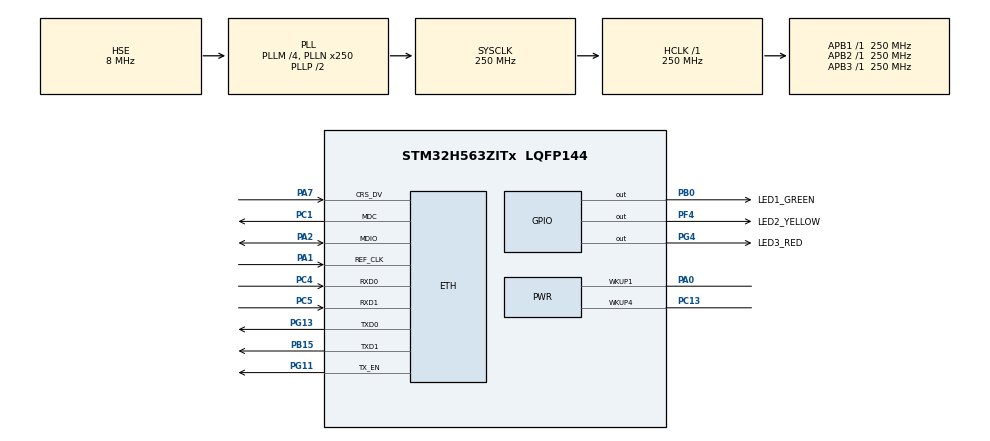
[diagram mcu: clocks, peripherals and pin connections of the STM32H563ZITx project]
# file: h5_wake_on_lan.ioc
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BOOTPATH.BootPathName=LEGACY
BOOTPATH.UserSelectedBootPath=LEGACY
CORTEX_M33_NS.userName=CORTEX_M33
ETH.MediaInterface=HAL_ETH_RMII_MODE
Mcu.Family=STM32H5
Mcu.Name=STM32H563ZITx
Mcu.Package=LQFP144
NETXDUO.ETH_ON=1
NETXDUO.Initialize_TCP_protocol=false
NETXDUO.LAN_8742=1
NETXDUO.NX_APP_IP_INSTANCE_THREAD_SIZE=1024 * 2
NETXDUO.NX_APP_MEM_POOL_SIZE=1024 * 30
NETXDUO.NX_APP_PACKET_POOL_SIZE=150
NETXDUO.NX_APP_THREAD_STACK_SIZE=1024 * 2
NETXDUO.NX_ENABLE_INTERFACE_CAPABILITY=true
NETXDUO.NetXDuo_Generate_Init_Code=true
NVIC.ETH_IRQn=true\:7\:0\:true\:false\:true\:false\:true\:true\:true
NVIC.ETH_WKUP_IRQn=true\:0\:0\:false\:false\:true\:false\:true\:true\:true
NVIC.PriorityGroup=NVIC_PRIORITYGROUP_4
NVIC.TIM6_IRQn=true\:15\:0\:false\:false\:true\:false\:false\:true\:true
NVIC.TimeBase=TIM6_IRQn
NVIC.TimeBaseIP=TIM6
NetXDuo.BSP.number=1
NetXDuo0.BSP.STBoard=false
NetXDuo0.BSP.api=BSP_COMPONENT_DRIVER
NetXDuo0.BSP.component=lan8742
NetXDuo0.BSP.instance=lan8742
NetXDuo0.BSP.name=LAN_Component
NetXDuo0.BSP.semaphore=SEMA_lan8742
NetXDuo0.BSP.solution=lan8742
PA0.Mode=WakeUp1
PA0.Signal=PWR_WKUP1
PA1.Mode=RMII
PA1.Signal=ETH_REF_CLK
PA2.Mode=RMII
PA2.Signal=ETH_MDIO
PA7.Mode=RMII
PA7.Signal=ETH_CRS_DV
PB0.GPIO_Label=LED1_GREEN
PB0.Signal=GPIO_Output
PB15.Mode=RMII
PB15.Signal=ETH_TXD1
PC1.Mode=RMII
PC1.Signal=ETH_MDC
PC13.Mode=WakeUp4
PC13.Signal=PWR_WKUP4
PC4.Mode=RMII
PC4.Signal=ETH_RXD0
PC5.Mode=RMII
PC5.Signal=ETH_RXD1
PF4.GPIO_Label=LED2_YELLOW
PF4.Signal=GPIO_Output
PG11.Mode=RMII
PG11.Signal=ETH_TX_EN
PG13.Mode=RMII
PG13.Signal=ETH_TXD0
PG4.GPIO_Label=LED3_RED
PG4.Signal=GPIO_Output
PH0-OSC_IN(PH0).Mode=HSE-DIG-External-Clock-Source
PH0-OSC_IN(PH0).Signal=RCC_OSC_IN
ProjectManager.HeapSize=0x200
ProjectManager.StackSize=0x400
ProjectManager.TargetToolchain=STM32CubeIDE
RCC.ADCFreq_Value=250000000
RCC.AHBFreq_Value=250000000
RCC.APB1Freq_Value=250000000
RCC.APB1TimFreq_Value=250000000
RCC.APB2Freq_Value=250000000
RCC.APB2TimFreq_Value=250000000
RCC.APB3Freq_Value=250000000
RCC.CSI_VALUE=4000000
RCC.CortexFreq_Value=250000000
RCC.EPOD_VALUE=8000000
RCC.HCLKFreq_Value=250000000
RCC.HSE_VALUE=8000000
RCC.HSI48_VALUE=48000000
RCC.HSI_VALUE=64000000
RCC.LSE_VALUE=32768
RCC.LSIRC_VALUE=32000
RCC.PLLFRACN=0
RCC.PLLM=4
RCC.PLLN=250
RCC.PLLSourceVirtual=RCC_PLL1_SOURCE_HSE
RCC.SYSCLKFreq_VALUE=250000000
RCC.SYSCLKSource=RCC_SYSCLKSOURCE_PLLCLK
RCC.USBFreq_Value=48000000
RCC.VCOOutputFreq_Value=500000000
VP_BOOTPATH_VS_BOOTPATH.Mode=BP_Activate
VP_ICACHE_VS_ICACHE.Mode=DefaultMode
VP_MEMORYMAP_VS_MEMORYMAP.Mode=CurAppReg
VP_NETXDUO_VS_EthernetOoPhyOoInterface.Mode=LAN8742_Phy_Interface
VP_NETXDUO_VS_NXOoCore.Mode=NX_Core
VP_NETXDUO_VS_NetworkOoInterface.Mode=Ethernet_Interface
VP_PWR_VS_DBSignals.Mode=DisableDeadBatterySignals
VP_PWR_VS_LPOM.Mode=PowerOptimisation
VP_PWR_VS_SECSignals.Mode=Security/Privilege
VP_SYS_VS_tim6.Mode=TIM6
VP_THREADX_VS_RTOSJjThreadXJjCoreJjDefault.Mode=Core_Default
board=custom

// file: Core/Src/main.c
/* USER CODE BEGIN Header */
/**
  ******************************************************************************
  * @file           : main.c
  * @brief          : Main program body
  ******************************************************************************
  * @attention
  *
  * Copyright (c) 2024 STMicroelectronics.
  * All rights reserved.
  *
  * This software is licensed under terms that can be found in the LICENSE file
  * in the root directory of this software component.
  * If no LICENSE file comes with this software, it is provided AS-IS.
  *
  ******************************************************************************
  */
/* USER CODE END Header */
#include "app_threadx.h"
#include "main.h"
#include "string.h"

ETH_TxPacketConfig TxConfig;
ETH_DMADescTypeDef  DMARxDscrTab[ETH_RX_DESC_CNT]; /* Ethernet Rx DMA Descriptors */
ETH_DMADescTypeDef  DMATxDscrTab[ETH_TX_DESC_CNT]; /* Ethernet Tx DMA Descriptors */

ETH_HandleTypeDef heth;

/* USER CODE BEGIN PV */
UCHAR memory_area[MEMORY_SIZE];
/* USER CODE END PV */

void SystemClock_Config(void);
static void MX_GPIO_Init(void);
static void MX_ETH_Init(void);
static void MX_ICACHE_Init(void);

int main(void)
{

  /* MCU Configuration--------------------------------------------------------*/

  /* Reset of all peripherals, Initializes the Flash interface and the Systick. */
  HAL_Init();

  /* Configure the system clock */
  SystemClock_Config();

  /* Initialize all configured peripherals */
  MX_GPIO_Init();
  MX_ETH_Init();
  MX_ICACHE_Init();
  /* USER CODE BEGIN 2 */
  // Inizializzazione dell'area di memoria con valori dummy
  for (ULONG i = 0; i < MEMORY_SIZE; i++)
  {
    memory_area[i] = 'a';
  }
  /* USER CODE END 2 */

  MX_ThreadX_Init();

  /* We should never get here as control is now taken by the scheduler */
  /* Infinite loop */
  while (1)
  {

  }
}

void SystemClock_Config(void)
{
  RCC_OscInitTypeDef RCC_OscInitStruct = {0};
  RCC_ClkInitTypeDef RCC_ClkInitStruct = {0};

  /** Configure the main internal regulator output voltage
  */
  __HAL_PWR_VOLTAGESCALING_CONFIG(PWR_REGULATOR_VOLTAGE_SCALE0);

  while(!__HAL_PWR_GET_FLAG(PWR_FLAG_VOSRDY)) {}

  /** Initializes the RCC Oscillators according to the specified parameters
  * in the RCC_OscInitTypeDef structure.
  */
  RCC_OscInitStruct.OscillatorType = RCC_OSCILLATORTYPE_HSE;
  RCC_OscInitStruct.HSEState = RCC_HSE_BYPASS_DIGITAL;
  RCC_OscInitStruct.PLL.PLLState = RCC_PLL_ON;
  RCC_OscInitStruct.PLL.PLLSource = RCC_PLL1_SOURCE_HSE;
  RCC_OscInitStruct.PLL.PLLM = 4;
  RCC_OscInitStruct.PLL.PLLN = 250;
  RCC_OscInitStruct.PLL.PLLP = 2;
  RCC_OscInitStruct.PLL.PLLQ = 2;
  RCC_OscInitStruct.PLL.PLLR = 2;
  RCC_OscInitStruct.PLL.PLLRGE = RCC_PLL1_VCIRANGE_1;
  RCC_OscInitStruct.PLL.PLLVCOSEL = RCC_PLL1_VCORANGE_WIDE;
  RCC_OscInitStruct.PLL.PLLFRACN = 0;
  if (HAL_RCC_OscConfig(&RCC_OscInitStruct) != HAL_OK)
  {
    Error_Handler();
  }

  /** Initializes the CPU, AHB and APB buses clocks
  */
  RCC_ClkInitStruct.ClockType = RCC_CLOCKTYPE_HCLK|RCC_CLOCKTYPE_SYSCLK
                              |RCC_CLOCKTYPE_PCLK1|RCC_CLOCKTYPE_PCLK2
                              |RCC_CLOCKTYPE_PCLK3;
  RCC_ClkInitStruct.SYSCLKSource = RCC_SYSCLKSOURCE_PLLCLK;
  RCC_ClkInitStruct.AHBCLKDivider = RCC_SYSCLK_DIV1;
  RCC_ClkInitStruct.APB1CLKDivider = RCC_HCLK_DIV1;
  RCC_ClkInitStruct.APB2CLKDivider = RCC_HCLK_DIV1;
  RCC_ClkInitStruct.APB3CLKDivider = RCC_HCLK_DIV1;

  if (HAL_RCC_ClockConfig(&RCC_ClkInitStruct, FLASH_LATENCY_5) != HAL_OK)
  {
    Error_Handler();
  }
}

static void MX_ETH_Init(void)
{

   static uint8_t MACAddr[6];

  heth.Instance = ETH;
  MACAddr[0] = 0x00;
  MACAddr[1] = 0x80;
  MACAddr[2] = 0xE1;
  MACAddr[3] = 0x00;
  MACAddr[4] = 0x00;
  MACAddr[5] = 0x00;
  heth.Init.MACAddr = &MACAddr[0];
  heth.Init.MediaInterface = HAL_ETH_RMII_MODE;
  heth.Init.TxDesc = DMATxDscrTab;
  heth.Init.RxDesc = DMARxDscrTab;
  heth.Init.RxBuffLen = 1524;

  if (HAL_ETH_Init(&heth) != HAL_OK)
  {
    Error_Handler();
  }

  memset(&TxConfig, 0 , sizeof(ETH_TxPacketConfig));
  TxConfig.Attributes = ETH_TX_PACKETS_FEATURES_CSUM | ETH_TX_PACKETS_FEATURES_CRCPAD;
  TxConfig.ChecksumCtrl = ETH_CHECKSUM_IPHDR_PAYLOAD_INSERT_PHDR_CALC;
  TxConfig.CRCPadCtrl = ETH_CRC_PAD_INSERT;

}

static void MX_ICACHE_Init(void)
{

  /** Enable instruction cache (default 2-ways set associative cache)
  */
  if (HAL_ICACHE_Enable() != HAL_OK)
  {
    Error_Handler();
  }

}

static void MX_GPIO_Init(void)
{
  GPIO_InitTypeDef GPIO_InitStruct = {0};

  /* GPIO Ports Clock Enable */
  __HAL_RCC_GPIOC_CLK_ENABLE();
  __HAL_RCC_GPIOF_CLK_ENABLE();
  __HAL_RCC_GPIOH_CLK_ENABLE();
  __HAL_RCC_GPIOA_CLK_ENABLE();
  __HAL_RCC_GPIOB_CLK_ENABLE();
  __HAL_RCC_GPIOG_CLK_ENABLE();

  /*Configure GPIO pin Output Level */
  HAL_GPIO_WritePin(LED2_YELLOW_GPIO_Port, LED2_YELLOW_Pin, GPIO_PIN_RESET);

  /*Configure GPIO pin Output Level */
  HAL_GPIO_WritePin(LED1_GREEN_GPIO_Port, LED1_GREEN_Pin, GPIO_PIN_RESET);

  /*Configure GPIO pin Output Level */
  HAL_GPIO_WritePin(LED3_RED_GPIO_Port, LED3_RED_Pin, GPIO_PIN_RESET);

  /*Configure GPIO pin : LED2_YELLOW_Pin */
  GPIO_InitStruct.Pin = LED2_YELLOW_Pin;
  GPIO_InitStruct.Mode = GPIO_MODE_OUTPUT_PP;
  GPIO_InitStruct.Pull = GPIO_NOPULL;
  GPIO_InitStruct.Speed = GPIO_SPEED_FREQ_LOW;
  HAL_GPIO_Init(LED2_YELLOW_GPIO_Port, &GPIO_InitStruct);

  /*Configure GPIO pin : LED1_GREEN_Pin */
  GPIO_InitStruct.Pin = LED1_GREEN_Pin;
  GPIO_InitStruct.Mode = GPIO_MODE_OUTPUT_PP;
  GPIO_InitStruct.Pull = GPIO_NOPULL;
  GPIO_InitStruct.Speed = GPIO_SPEED_FREQ_LOW;
  HAL_GPIO_Init(LED1_GREEN_GPIO_Port, &GPIO_InitStruct);

  /*Configure GPIO pin : LED3_RED_Pin */
  GPIO_InitStruct.Pin = LED3_RED_Pin;
  GPIO_InitStruct.Mode = GPIO_MODE_OUTPUT_PP;
  GPIO_InitStruct.Pull = GPIO_NOPULL;
  GPIO_InitStruct.Speed = GPIO_SPEED_FREQ_LOW;
  HAL_GPIO_Init(LED3_RED_GPIO_Port, &GPIO_InitStruct);

}

/* USER CODE BEGIN 4 */
void standby (void){
  HAL_PWR_DisableWakeUpPin(PWR_WKUP1);
  HAL_PWR_EnableWakeUpPin(PWR_WKUP1);
  HAL_PWR_EnterSTANDBYMode();
}
/* USER CODE END 4 */

void HAL_TIM_PeriodElapsedCallback(TIM_HandleTypeDef *htim)
{
  if (htim->Instance == TIM6) {
    HAL_IncTick();
  }
}

void Error_Handler(void)
{
  /* USER CODE BEGIN Error_Handler_Debug */
  /* User can add his own implementation to report the HAL error return state */
	 HAL_PWR_DisableWakeUpPin(PWR_WKUP1);
		  	    HAL_PWR_EnableWakeUpPin(PWR_WKUP1);
		  	    HAL_PWR_EnterSTANDBYMode();
  /* USER CODE END Error_Handler_Debug */
}
